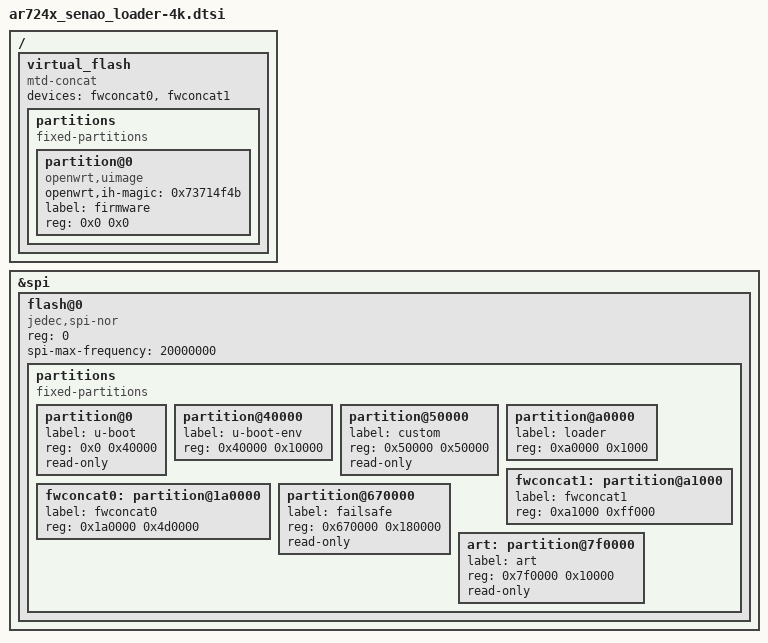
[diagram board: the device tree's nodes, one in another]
// SPDX-License-Identifier: GPL-2.0-or-later OR MIT

#include <dt-bindings/mtd/partitions/uimage.h>

/ {
	virtual_flash {
		compatible = "mtd-concat";

		devices = <&fwconcat0 &fwconcat1>;

		partitions {
			compatible = "fixed-partitions";
			#address-cells = <1>;
			#size-cells = <1>;

			partition@0 {
				compatible = "openwrt,uimage", "denx,uimage";
				openwrt,ih-magic = <0x73714f4b>;
				label = "firmware";
				reg = <0x0 0x0>;
			};
		};
	};
};

&spi {
	status = "okay";

	flash@0 {
		compatible = "jedec,spi-nor";
		reg = <0>;
		spi-max-frequency = <20000000>;

		partitions {
			compatible = "fixed-partitions";
			#address-cells = <1>;
			#size-cells = <1>;

			partition@0 {
				label = "u-boot";
				reg = <0x0 0x40000>;
				read-only;
			};

			partition@40000 {
				label = "u-boot-env";
				reg = <0x40000 0x10000>;
			};

			partition@50000 {
				label = "custom";
				reg = <0x50000 0x50000>;
				read-only;
			};

			partition@a0000 {
				label = "loader";
				reg = <0xa0000 0x1000>;
			};

			fwconcat1: partition@a1000 {
				label = "fwconcat1";
				reg = <0xa1000 0xff000>;
			};

			fwconcat0: partition@1a0000 {
				label = "fwconcat0";
				reg = <0x1a0000 0x4d0000>;
			};

			partition@670000 {
				label = "failsafe";
				reg = <0x670000 0x180000>;
				read-only;
			};

			art: partition@7f0000 {
				label = "art";
				reg = <0x7f0000 0x10000>;
				read-only;
			};
		};
	};
};
